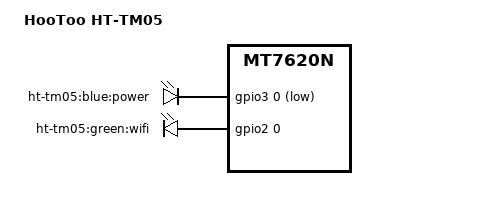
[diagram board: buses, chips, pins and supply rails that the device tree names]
// SPDX-License-Identifier: GPL-2.0-or-later OR MIT
/dts-v1/;

#include "mt7620n_sunvalley.dtsi"

/ {
	compatible = "hootoo,ht-tm05", "ralink,mt7620n-soc";
	model = "HooToo HT-TM05";

	leds {
		compatible = "gpio-leds";

		led_power: power {
			label = "ht-tm05:blue:power";
			gpios = <&gpio3 0 GPIO_ACTIVE_LOW>;
			default-state = "on";
		};

		wifi {
			label = "ht-tm05:green:wifi";
			gpios = <&gpio2 0 GPIO_ACTIVE_HIGH>;
			linux,default-trigger = "phy0tpt";
		};
	};
};
